AUTOSAR XML (schema 00049)
package /SwComponent/AdaptiveApplication
  adaptive application sw component type Actuator
    require port Sensor: required-interface=Sensor
  adaptive application sw component type CM
  adaptive application sw component type EM
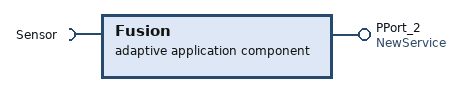
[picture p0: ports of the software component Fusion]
  adaptive application sw component type Fusion
    require port Sensor: required-interface=Sensor
    provide port PPort_2: provided-interface=NewService
  adaptive application sw component type Sensor
    provide port Sensor: provided-interface=Sensor
  adaptive application sw component type NewSWC_1
    require port RPort_1: required-interface=NewService
package /SwComponent/Composition
  composition sw component type HPC
    5 x component:
      Actuator: type=Actuator
      AdaptiveApplication0: type=EM
      AdaptiveApplication1: type=CM
      Fusion: type=Fusion
      Sensor: type=Sensor
  composition sw component type System
    component Composition1: type=HPC
package /AdaptiveApplication/DltConfig
  5 x dlt log channel to process mapping:
    DltLogChannelToProcessMapping_Actuator_TO_Actuator: dlt-log-channel=Actuator, process=Actuator
    DltLogChannelToProcessMapping_CM_TO_CM: dlt-log-channel=CM, process=CM
    DltLogChannelToProcessMapping_EM_TO_EM: dlt-log-channel=EM, process=EM
    DltLogChannelToProcessMapping_Fusion_TO_Fusion: dlt-log-channel=Fusion, process=Fusion
    DltLogChannelToProcessMapping_Sensor_TO_Sensor: dlt-log-channel=Sensor, process=Sensor
package /AdaptiveApplication/Executable
  5 x executable, all with category=APPLICATION_LEVEL, logging-behavior=USES-LOGGING, reporting-behavior=REPORTS-EXECUTION-STATE, version=1.0.0:
    Actuator
      root sw component prototype AA: application-type=Actuator
    CM
      root sw component prototype RootSwComponent: application-type=CM
    EM
      root sw component prototype RootSwComponent: application-type=EM
    Fusion
      root sw component prototype AA: application-type=Fusion
    Sensor
      root sw component prototype AA: application-type=Sensor
package /AdaptiveApplication/Manifest
  service instance to port prototype mapping Actuator_AA_Sensor: port-prototype=AA.Sensor, service-instance=Actuator_Sensor
  service instance to port prototype mapping Fusion_AA_Sensor: port-prototype=AA.Sensor, service-instance=Fusion_Sensor
  service instance to port prototype mapping Sensor_AA_Sensor: port-prototype=AA.Sensor, service-instance=Provider_Sensor
package /AdaptiveApplication/Process
  5 x process:
    Actuator: executable=Actuator, state-dependent-startup-config{execution-dependency=CM.Running, function-group-state=MachineFG.Startup, resource-group=ResourceGroup, startup-config=AA}
      process state machine Actuator: type=ProcessState
    CM: executable=CM, state-dependent-startup-config{function-group-state=[MachineFG.Startup, MachineFG.Shutdown, MachineFG.Restart, MachineFG.Verify], resource-group=ResourceGroup, startup-config=CM}
      process state machine CM: type=ProcessState
    EM: executable=EM
    Fusion: executable=Fusion, state-dependent-startup-config{execution-dependency=CM.Running, function-group-state=MachineFG.Startup, resource-group=ResourceGroup, startup-config=AA}
      process state machine Fusion: type=ProcessState
    Sensor: executable=Sensor, state-dependent-startup-config{execution-dependency=CM.Running, function-group-state=MachineFG.Startup, resource-group=ResourceGroup, startup-config=AA}
      process state machine Sensor: type=ProcessState
package /AdaptiveApplication/StartupConfig
  startup config set StartupConfig
    startup config AA: scheduling-policy=SCHED_OTHER, scheduling-priority=0, timeout={enter-timeout-value=1.0, exit-timeout-value=1.0}
    startup config CM: scheduling-policy=SCHED_OTHER, scheduling-priority=0, timeout={enter-timeout-value=1.0, exit-timeout-value=1.0}
    startup config EM: scheduling-policy=SCHED_OTHER, scheduling-priority=0, timeout={enter-timeout-value=1.0, exit-timeout-value=1.0}
package /DataType/Implementation/CPP
  13 x std cpp implementation data type:
    ByteArray: category=VECTOR, cpp-template-argument=uint8_t
      namespaces:
        symbol props aa
        symbol props type
    String: category=STRING
      namespaces:
        symbol props aa
        symbol props type
    bool: category=VALUE, type-emitter=FundamentalType
    double: category=VALUE, type-emitter=FundamentalType
    float: category=VALUE, type-emitter=FundamentalType
    int16_t: category=VALUE, header-file=cstdint
    int32_t: category=VALUE, header-file=cstdint
    int64_t: category=VALUE, header-file=cstdint
    int8_t: category=VALUE, header-file=cstdint
    uint16_t: category=VALUE, header-file=cstdint
    uint32_t: category=VALUE, header-file=cstdint
    uint64_t: category=VALUE, header-file=cstdint
    uint8_t: category=VALUE, header-file=cstdint
package /PortInterface/Service
  service interface Sensor
    namespaces:
      symbol props sensor
      symbol props service
    events:
      data SensorData: type=ByteArray
    methods:
      operation Calculation: fire-and-forget=false
        5 x arg, all with type=float:
          front: direction=IN
          rear: direction=IN
          left: direction=IN
          right: direction=IN
          result: direction=OUT
package /Platform
  machine HPC: machine-design=HPC, trusted-platform-executable-launch-behavior=NO-TRUSTED-PLATFORM-SUPPORT
    module-instantiations:
      generic module instantiation CM: category=COMMUNICATION_MANAGEMENT
      log and trace instantiation Log: dlt-ecu-id=ECU
        5 x dlt log channel, all with log-trace-log-modes=CONSOLE:
          Actuator: application-id=ACTA, context-id=ACTA, log-trace-default-log-level=VERBOSE
          CM: application-id=CM, context-id=CM, log-trace-default-log-level=ERROR
          EM: application-id=EM, context-id=EM, log-trace-default-log-level=ERROR
          Fusion: application-id=FUSN, context-id=FUSN, log-trace-default-log-level=VERBOSE
          Sensor: application-id=SENS, context-id=SENS, log-trace-default-log-level=VERBOSE
      os module instantiation POSIX
        resource group ResourceGroup
    processor CPU
      4 x processor core:
        Core{0..3}: core-id={0..3}
package /Platform/FunctionGroup
  function group set FunctionGroup
    function-groups:
      mode declaration group prototype MachineFG: type=MachineState
package /Platform/ProcessToMachine
  process to machine mapping set ProcessToMachineMapping
    5 x process to machine mapping, all with machine=HPC:
      ProcessToMachineMapping_Actuator_TO_HPCMachine_TO_UnknownModule: process=Actuator
      ProcessToMachineMapping_CM_TO_HPCMachine_TO_UnknownModule: process=CM
      ProcessToMachineMapping_EM_TO_HPCMachine_TO_UnknownModule: process=EM
      ProcessToMachineMapping_Fusion_TO_HPCMachine_TO_UnknownModule: process=Fusion
      ProcessToMachineMapping_Sensor_TO_HPCMachine_TO_UnknownModule: process=Sensor
package /System
  system System: category=SYSTEM_DESIGN_DESCRIPTION, system-version=1.0.0
    system mapping SystemMapping
      sw-mappings:
        swc to ecu mapping SwMapping0: component=RootSoftwareComposition.Composition1.Composition1
    root-software-compositions:
      root sw composition prototype RootSoftwareComposition: software-composition=System
package /System/Service/Deployment
  someip service interface deployment Sensor: service-interface=Sensor, service-interface-id=11, service-interface-version={major-version=1, minor-version=0}
    someip event deployment SensorData: event=SensorData, event-id=1, transport-protocol=UDP
    someip method deployment Calculation: method=Calculation, method-id=1, transport-protocol=UDP
    someip event group Eventgroup_SensorData: event-group-id=1, event=SensorData
package /System/Service/Endpoint
  someip service instance to machine mapping Consumer_Actuator_Endpoint: communication-connector=eth0, service-instance=Actuator_Sensor, tcp-port=33000, udp-port=33000
  someip service instance to machine mapping Consumer_Fusion_Endpoint: communication-connector=eth0, service-instance=Fusion_Sensor, tcp-port=34000, udp-port=34000
  someip service instance to machine mapping Provider_Sensor_Endpoint: communication-connector=eth0, service-instance=Provider_Sensor, tcp-port=23000, udp-port=23000
package /System/Service/Instance
  required someip service instance Actuator_Sensor: service-interface-deployment=Sensor, someip-method-props=Calculation, required-minor-version=ANY, required-service-instance-id=ANY, sd-client-config=SdClientConfig, version-driven-find-behavior=EXACT-OR-ANY-MINOR-VERSION
    someip required event group Eventgroup_SensorData: event-group=Eventgroup_SensorData, sd-client-event-group-timing-config=SdEventgroupConfig
  required someip service instance Fusion_Sensor: service-interface-deployment=Sensor, someip-method-props=Calculation, required-minor-version=ANY, required-service-instance-id=ANY, sd-client-config=SdClientConfig, version-driven-find-behavior=EXACT-OR-ANY-MINOR-VERSION
    someip required event group Eventgroup_SensorData: event-group=Eventgroup_SensorData, sd-client-event-group-timing-config=SdEventgroupConfig
  provided someip service instance Provider_Sensor: service-interface-deployment=Sensor, someip-event-props=SensorData, someip-method-props=Calculation, sd-server-config=SdServerConfig, service-instance-id=1
    someip provided event group Eventgroup_SensorData: event-group=Eventgroup_SensorData, multicast-threshold=0
package /System/Service/TimingConfig
  someip sd client service instance config SdClientConfig: initial-find-behavior={initial-delay-max-value=0.1, initial-delay-min-value=0.01, initial-repetitions-base-delay=0.2, initial-repetitions-max=3}, service-find-time-to-live=16777215
  someip sd client event group timing config SdEventgroupConfig: request-response-delay={max-value=0.0, min-value=0.0}, time-to-live=16777215
  someip sd server service instance config SdServerConfig: initial-offer-behavior={initial-delay-max-value=0.1, initial-delay-min-value=0.01, initial-repetitions-base-delay=0.2, initial-repetitions-max=3}, offer-cyclic-delay=1.0, request-response-delay={max-value=0.0, min-value=0.0}, service-offer-time-to-live=16777215
package /System/VehicleTopology/Cluster
  ethernet cluster EthernetCluster
    ethernet physical channel PhysicalChannel: category=WIRED, comm-connectors=eth0
      network endpoint EcuEndpoint: network-endpoint-addresses=ipv-4-configuration={ipv-4-address=127.0.0.1, ipv-4-address-source=FIXED}
      network endpoint SdMulticast: network-endpoint-addresses=ipv-4-configuration={ipv-4-address=224.0.0.1, ipv-4-address-source=FIXED}
package /System/VehicleTopology/Ecu
  machine design HPC: service-discover-configs=someip-service-discovery={multicast-sd-ip-address=SdMulticast, someip-service-discovery-port=30490}
    user defined communication connector IPC
    ethernet communication connector eth0: unicast-network-endpoint=EcuEndpoint
package /StateMachine
  mode declaration group MachineState: initial-mode=Off
    5 x mode:
      Off
      Restart
      Shutdown
      Startup
      Verify
  mode declaration group ProcessState: initial-mode=Idle
    4 x mode:
      Idle
      Running
      Starting
      Terminated
